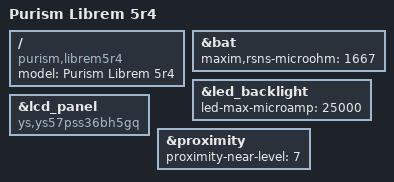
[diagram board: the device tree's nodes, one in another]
/dts-v1/;
#include "imx8mq-librem5-r3.dtsi"
/ {
	model = "Purism Librem 5r4";
	compatible = "purism,librem5r4", "purism,librem5", "fsl,imx8mq";
};
&bat {
	maxim,rsns-microohm = <1667>;
};
&led_backlight {
	led-max-microamp = <25000>;
};
&lcd_panel {
	compatible = "ys,ys57pss36bh5gq";
};
&proximity {
	proximity-near-level = <7>;
};
